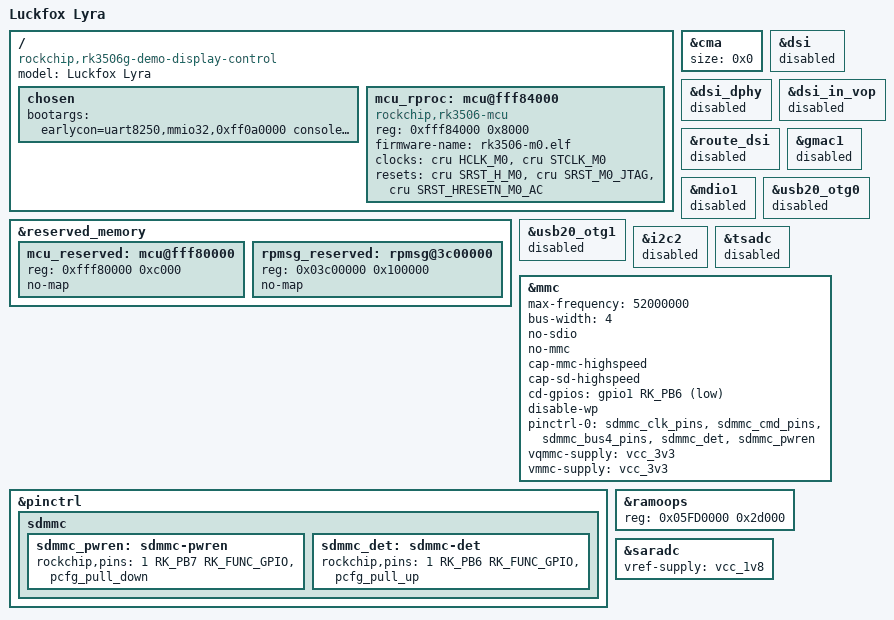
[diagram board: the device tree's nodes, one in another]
// SPDX-License-Identifier: (GPL-2.0+ OR MIT)
/*
 * Minimal SD-card boot DTS for Luckfox Lyra (RK3506G).
 *
 * Stripped to the bare essentials for initial bring-up:
 *   - FIQ debugger serial console
 *   - SD card (SDMMC)
 *   - Regulators needed by SDMMC
 *
 * Everything else (display, USB, I2C, touch, audio) is disabled or omitted
 * to avoid probe failures that cascade through fw_devlink and pinctrl.
 */

/dts-v1/;

#include "rk3506-luckfox-lyra.dtsi"

/ {
	model = "Luckfox Lyra";
	compatible = "rockchip,rk3506g-demo-display-control", "rockchip,rk3506";

	chosen {
		bootargs = "earlycon=uart8250,mmio32,0xff0a0000 console=ttyFIQ0";
	};

	/* ---- Cortex-M0 remoteproc ---- */
	mcu_rproc: mcu@fff84000 {
		compatible = "rockchip,rk3506-mcu";
		reg = <0xfff84000 0x8000>;
		firmware-name = "rk3506-m0.elf";

		clocks = <&cru HCLK_M0>, <&cru STCLK_M0>;
		resets = <&cru SRST_H_M0>, <&cru SRST_M0_JTAG>,
			 <&cru SRST_HRESETN_M0_AC>;
		reset-names = "h_m0", "m0_jtag", "hresetn_m0_ac";
	};
};

/* ---- M0 reserved memory ---- */
&reserved_memory {
	mcu_reserved: mcu@fff80000 {
		reg = <0xfff80000 0xc000>;
		no-map;
	};

	rpmsg_reserved: rpmsg@3c00000 {
		reg = <0x03c00000 0x100000>;
		no-map;
	};
};

/* ---- Disable everything we don't need for SD card boot ---- */

/* Display disabled — reclaim the 32MB CMA the board DTSI reserves for framebuffers */
&cma {
	size = <0x0>;
};

&dsi {
	status = "disabled";
};

&dsi_dphy {
	status = "disabled";
};

&dsi_in_vop {
	status = "disabled";
};

&route_dsi {
	status = "disabled";
};

/* Ethernet */
&gmac1 {
	status = "disabled";
};

&mdio1 {
	status = "disabled";
};

/* USB — disable for now, re-enable later */
&usb20_otg0 {
	status = "disabled";
};

&usb20_otg1 {
	status = "disabled";
};

/* I2C — not needed for boot */
&i2c2 {
	status = "disabled";
};

/* TSADC — remove pinctrl reference that pulls in rmio */
&tsadc {
	status = "disabled";
};

/* ---- Enable only what we need ---- */

/* SD card */
&mmc {
	max-frequency = <52000000>;
	bus-width = <4>;
	no-sdio;
	no-mmc;
	cap-mmc-highspeed;
	cap-sd-highspeed;
	cd-gpios = <&gpio1 RK_PB6 GPIO_ACTIVE_LOW>;
	disable-wp;
	pinctrl-names = "default";
	pinctrl-0 = <&sdmmc_clk_pins &sdmmc_cmd_pins &sdmmc_bus4_pins &sdmmc_det &sdmmc_pwren>;
	vqmmc-supply = <&vcc_3v3>;
	vmmc-supply = <&vcc_3v3>;
	status = "okay";
};

&pinctrl {
	sdmmc {
		/omit-if-no-ref/
		sdmmc_pwren: sdmmc-pwren {
			rockchip,pins = <1 RK_PB7 RK_FUNC_GPIO &pcfg_pull_down>;
		};

		sdmmc_det: sdmmc-det {
			rockchip,pins = <1 RK_PB6 RK_FUNC_GPIO &pcfg_pull_up>;
		};
	};
};

/* Move ramoops to high memory — the default 0x83000 overlaps with the DTB
 * which U-Boot loads at ~0x63000. The kernel doesn't copy FDT property data
 * during unflatten, so ramoops writes corrupt DTB values in-place. */
&ramoops {
	reg = <0x05FD0000 0x2d000>;
};

&saradc {
	vref-supply = <&vcc_1v8>;
	status = "okay";
};
